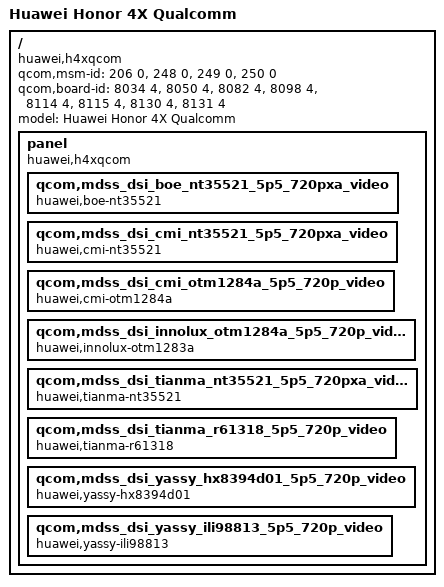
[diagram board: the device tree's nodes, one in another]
// SPDX-License-Identifier: GPL-2.0-only

/dts-v1/;
#include <skeleton.dtsi>

/ {
	qcom,msm-id = <206 0>,<248 0>,<249 0>,<250 0>;
	qcom,board-id = <8034 4>,<8050 4>,<8082 4>,<8098 4>,<8114 4>,<8115 4>,<8130 4>,<8131 4>;

	model = "Huawei Honor 4X Qualcomm";
	compatible = "huawei,h4xqcom", "qcom,msm8916", "lk2nd,device";

	panel {
		compatible = "huawei,h4xqcom";

		qcom,mdss_dsi_boe_nt35521_5p5_720pxa_video {
			compatible = "huawei,boe-nt35521";
		};
		qcom,mdss_dsi_cmi_nt35521_5p5_720pxa_video {
			compatible = "huawei,cmi-nt35521";
		};
                qcom,mdss_dsi_cmi_otm1284a_5p5_720p_video {
			compatible = "huawei,cmi-otm1284a";
		};
		qcom,mdss_dsi_innolux_otm1284a_5p5_720p_video {
			compatible = "huawei,innolux-otm1283a";
		};
		qcom,mdss_dsi_tianma_nt35521_5p5_720pxa_video {
			compatible = "huawei,tianma-nt35521";
		};
		qcom,mdss_dsi_tianma_r61318_5p5_720p_video {
			compatible = "huawei,tianma-r61318";
		};
		qcom,mdss_dsi_yassy_hx8394d01_5p5_720p_video {
			compatible = "huawei,yassy-hx8394d01";
		};
		qcom,mdss_dsi_yassy_ili98813_5p5_720p_video {
			compatible = "huawei,yassy-ili98813";
		};
	};
};
